# nrf54l15_enga_application register map
Vendor: Nordic Semiconductor; Series: nrf54l; File version: 1
CPU: CM33 r0p4, little endian, MPU, FPU, 3 interrupt priority bits, 176 interrupts, 4 SAU regions
Registers are 32-bit, read-write, reset 0x0 unless marked. A register's access mark holds for its fields unless they carry their own. Offsets are from the block's base; [hi:lo] are bit positions; lines under a group give offsets from that group; {n}, {i} and the like mark numbered series; 'fields as' and 'values as' point back to an identical list.

## GLOBAL_FICR_NS — Factory Information Configuration Registers
Base 0x00FFC000
0x300 INFO group — Device info
  0x00 CONFIGID ro reset 0xFFFFFFFF — Configuration identifier
    [15:0] HWID — Identification number for the HW
  {0x4+4j} DEVICEID[{j}] (j=0..1) ro reset 0xFFFFFFFF — Description collection: Device identifier
    [31:0] DEVICEID — 64 bit unique device identifier
  {0xC+4j} UUID[{j}] (j=0..3) reset 0xFFFFFFFF — Description collection: 128-bit Universally Unique IDentifier (UUID).
    [31:0] UUID — Device UUID [n].
  0x1C PART ro reset 0xFFFFFFFF — Part code
    [31:0] PART
      0x54B15=N54L15 (nRF54L15); 0xFFFFFFFF=Unspecified
  0x20 VARIANT ro reset 0xFFFFFFFF — Part Variant, Hardware version and Production configuration
    [31:0] VARIANT — Part Variant, Hardware version and Production configuration, encoded as ASCII
      0xFFFFFFFF=Unspecified
  0x24 PACKAGE ro reset 0xFFFFFFFF — Package option
    [31:0] PACKAGE
      0xFFFFFFFF=Unspecified
  0x28 RAM ro reset 0xFFFFFFFF — RAM variant
    [31:0] RAM
      0x100=K256 (256 kByte RAM); 0xFFFFFFFF=Unspecified
  0x2C RRAM ro reset 0xFFFFFFFF — RRAM variant
    [31:0] RRAM
      0x5F4=K1524 (1524 KByte RRAM); 0xFFFFFFFF=Unspecified
{0x380+4i} ER[{i}] (i=0..3) ro reset 0xFFFFFFFF — Description collection: Common encryption root key, word n
  [31:0] ER — Encryption Root, word n
{0x390+4i} IR[{i}] (i=0..3) ro reset 0xFFFFFFFF — Description collection: Common identity root key, word n
  [31:0] IR — Identity Root, word n
0x3A0 DEVICEADDRTYPE ro reset 0xFFFFFFFF — Device address type
  [0] DEVICEADDRTYPE
    0=Public address; 1=Random address
{0x3A4+4i} DEVICEADDR[{i}] (i=0..1) ro reset 0xFFFFFFFF — Description collection: Device address n
  [31:0] DEVICEADDR — 48 bit device address
{0x400+8i} TRIMCNF[{i}] (i=0..63) group — Unspecified
  0x00 ADDR ro reset 0xFFFFFFFF — Description cluster: Address of the register which will be written
    [31:0] Address
  0x04 DATA ro reset 0xFFFFFFFF — Description cluster: Data to be written into the register
0x600 NFC group — Unspecified
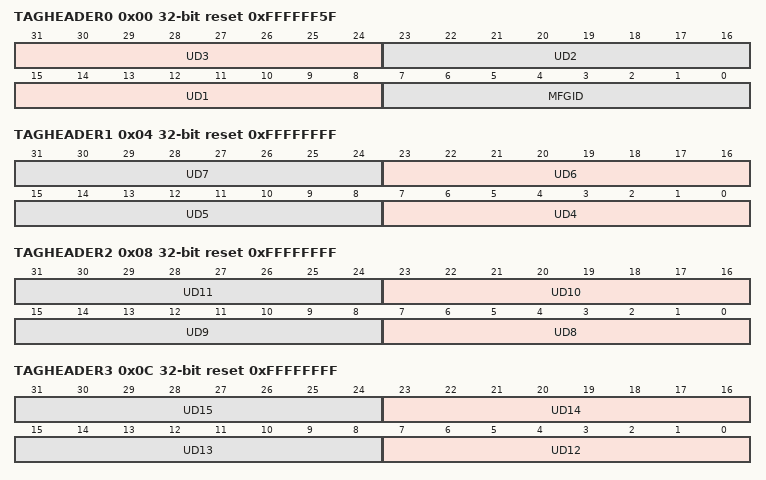
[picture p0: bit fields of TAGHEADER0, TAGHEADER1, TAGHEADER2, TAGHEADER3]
  0x00 TAGHEADER0 ro reset 0xFFFFFF5F — Default header for NFC Tag. Software can read these values to populate NFCID1_3RD_LAST, NFCID1_2ND_LAST and NFCID1_LAST.
    [31:24] UD3 — Unique identifier byte 3
    [23:16] UD2 — Unique identifier byte 2
    [15:8] UD1 — Unique identifier byte 1
    [7:0] MFGID — Default Manufacturer ID: Nordic Semiconductor ASA has ICM 0x5F
  0x04 TAGHEADER1 ro reset 0xFFFFFFFF — Default header for NFC Tag. Software can read these values to populate NFCID1_3RD_LAST, NFCID1_2ND_LAST and NFCID1_LAST.
    [8n-25:8n-32] UD{n} (n=4..7) — Unique identifier byte {n}
  0x08 TAGHEADER2 ro reset 0xFFFFFFFF — Default header for NFC Tag. Software can read these values to populate NFCID1_3RD_LAST, NFCID1_2ND_LAST and NFCID1_LAST.
    [8n-57:8n-64] UD{n} (n=8..11) — Unique identifier byte {n}
  0x0C TAGHEADER3 ro reset 0xFFFFFFFF — Default header for NFC Tag. Software can read these values to populate NFCID1_3RD_LAST, NFCID1_2ND_LAST and NFCID1_LAST.
    [8n-89:8n-96] UD{n} (n=12..15) — Unique identifier byte {n}
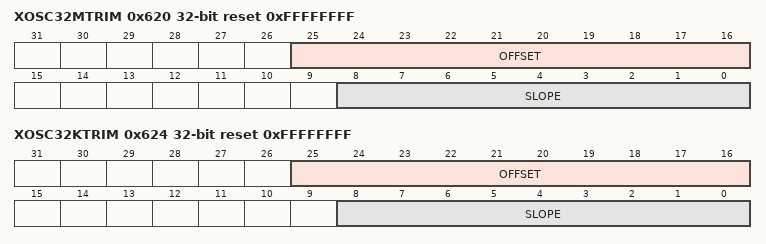
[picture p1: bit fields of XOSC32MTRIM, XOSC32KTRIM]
0x620 XOSC32MTRIM ro reset 0xFFFFFFFF — XOSC32M capacitor selection trim values
  [25:16] OFFSET — Offset trim factor on integer form
  [8:0] SLOPE — Slope trim factor on twos complement form
0x624 XOSC32KTRIM ro reset 0xFFFFFFFF — XOSC32K capacitor selection trim values
  fields as XOSC32MTRIM

## GLOBAL_UICR_S — User Information Configuration Registers
Base 0x00FFD000
{0x40+0x20*i} AUXAPPROTECT[{i}] (i=0..0) group — Access Port Protection Registers
  0x00 PROTECT0 rw-once reset 0xFFFFFFFF — Description cluster: Access port protection
    [31:0] PALL
      0x50FA50FA=Protected (Blocks debugger read/write access to all CPU registers and memory mapped addresses, and locks TAMPC PROTECT.AP[0] DBGEN signal protector.)
  0x1C PROTECT1 rw-once reset 0xFFFFFFFF — Description cluster: Access port protection register
    fields as AUXAPPROTECT[0].PROTECT0
{0x60+0x20*i} ERASEPROTECT[{i}] (i=0..0) group — Erase Protection Registers
  0x00 PROTECT0 rw-once reset 0xFFFFFFFF — Description cluster: Erase protection
    [31:0] PALL
      0x50FA50FA=Protected, the device cannot be erased using the CTRL-AP Erase all function and TAMPC PROTECT.ERASEPROTECT signal protector is locked
  0x1C PROTECT1 rw-once reset 0xFFFFFFFF — Description cluster: Erase protection
    fields as ERASEPROTECT[0].PROTECT0
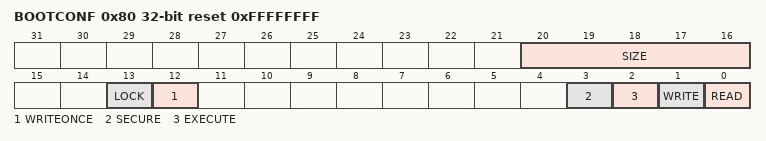
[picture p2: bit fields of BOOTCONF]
0x80 BOOTCONF rw-once reset 0xFFFFFFFF — Immutable boot region configuration.
  [20:16] SIZE — Immutable boot region size
  [13] LOCK — Enable lock of configuration register
    0=Disabled (Lock is disabled, and the RRAMC region configuration registers for the immutable boot region are writable.); 1=Enabled (Lock is enabled, and the RRAMC configuration registers for the immutable boot region are read-only.)
  [12] WRITEONCE
    0=Disabled (Write-once disabled); 1=Enabled (Write-once enabled)
  [3] SECURE — Secure access
    0=NonSecure (Both secure and non-secure access to region is allowed); 1=Secure (Only secure access to region is allowed)
  [2] EXECUTE — Execute access
    0=NotAllowed (Executing code from the region is not allowed); 1=Allowed (Executing code from the region is allowed)
  [1] WRITE — Write access
    0=NotAllowed (Writing to the region is not allowed); 1=Allowed (Writing to the region is allowed)
  [0] READ — Read access
    0=NotAllowed (Reading from the region is not allowed); 1=Allowed (Reading from the region is allowed)
0x200 USER group — Unspecified
  0x00 ROT group — Assets installed to establish initial Root of Trust in the device.
    {0x0+0x2C*k} PUBKEY[{k}] (k=0..3) group — Unspecified
      {0x0+4l} DIGEST[{l}] (l=0..7) rw-once reset 0xFFFFFFFF — Description collection: First 256 bits of SHA2-512 digest over RoT public key generation [n].
        [31:0] VALUE — Value for word [o] in the key digest [n].
      {0x20+4l} REVOKE[{l}] (l=0..2) rw-once reset 0xFFFFFFFF — Description collection: Revocation status for RoT public key generation [n].
        [31:0] STATUS — Revocation status.
          0xFFFFFFFF=NotRevoked (Key not revoked.)
    {0xB0+0x2C*k} AUTHOPKEY[{k}] (k=0..3) group — Unspecified
      {0x0+4l} DIGEST[{l}] (l=0..7) rw-once reset 0xFFFFFFFF — Description collection: First 256 bits of SHA2-512 digest over RoT authenticated operation public key generation [n].
        [31:0] VALUE — Value for word [o] in the key digest [n].
      {0x20+4l} REVOKE[{l}] (l=0..2) rw-once reset 0xFFFFFFFF — Description collection: Revocation status for RoT authenticated operation public key generation [n].
        fields as USER.ROT.PUBKEY[0].REVOKE[0]
{0x500+4i} OTP[{i}] (i=0..319) rw-once reset 0xFFFFFFFF — Description collection: One time programmable memory
  [31:0] OTP — OTP word

## Notices in the file
Copyright (c) 2010 - 2024, Nordic Semiconductor ASA All rights reserved.
SPDX-License-Identifier: BSD-3-Clause
Redistribution and use in source and binary forms, with or without
modification, are permitted provided that the following conditions are met:
1. Redistributions of source code must retain the above copyright notice, this
list of conditions and the following disclaimer.
2. Redistributions in binary form must reproduce the above copyright
notice, this list of conditions and the following disclaimer in the
documentation and/or other materials provided with the distribution.
3. Neither the name of Nordic Semiconductor ASA nor the names of its
contributors may be used to endorse or promote products derived from this
software without specific prior written permission.
THIS SOFTWARE IS PROVIDED BY THE COPYRIGHT HOLDERS AND CONTRIBUTORS "AS IS"
AND ANY EXPRESS OR IMPLIED WARRANTIES, INCLUDING, BUT NOT LIMITED TO, THE
IMPLIED WARRANTIES OF MERCHANTABILITY, AND FITNESS FOR A PARTICULAR PURPOSE
ARE DISCLAIMED. IN NO EVENT SHALL NORDIC SEMICONDUCTOR ASA OR CONTRIBUTORS BE
LIABLE FOR ANY DIRECT, INDIRECT, INCIDENTAL, SPECIAL, EXEMPLARY, OR
CONSEQUENTIAL DAMAGES (INCLUDING, BUT NOT LIMITED TO, PROCUREMENT OF
SUBSTITUTE GOODS OR SERVICES; LOSS OF USE, DATA, OR PROFITS; OR BUSINESS
INTERRUPTION) HOWEVER CAUSED AND ON ANY THEORY OF LIABILITY, WHETHER IN
CONTRACT, STRICT LIABILITY, OR TORT (INCLUDING NEGLIGENCE OR OTHERWISE)
ARISING IN ANY WAY OUT OF THE USE OF THIS SOFTWARE, EVEN IF ADVISED OF THE
POSSIBILITY OF SUCH DAMAGE.
